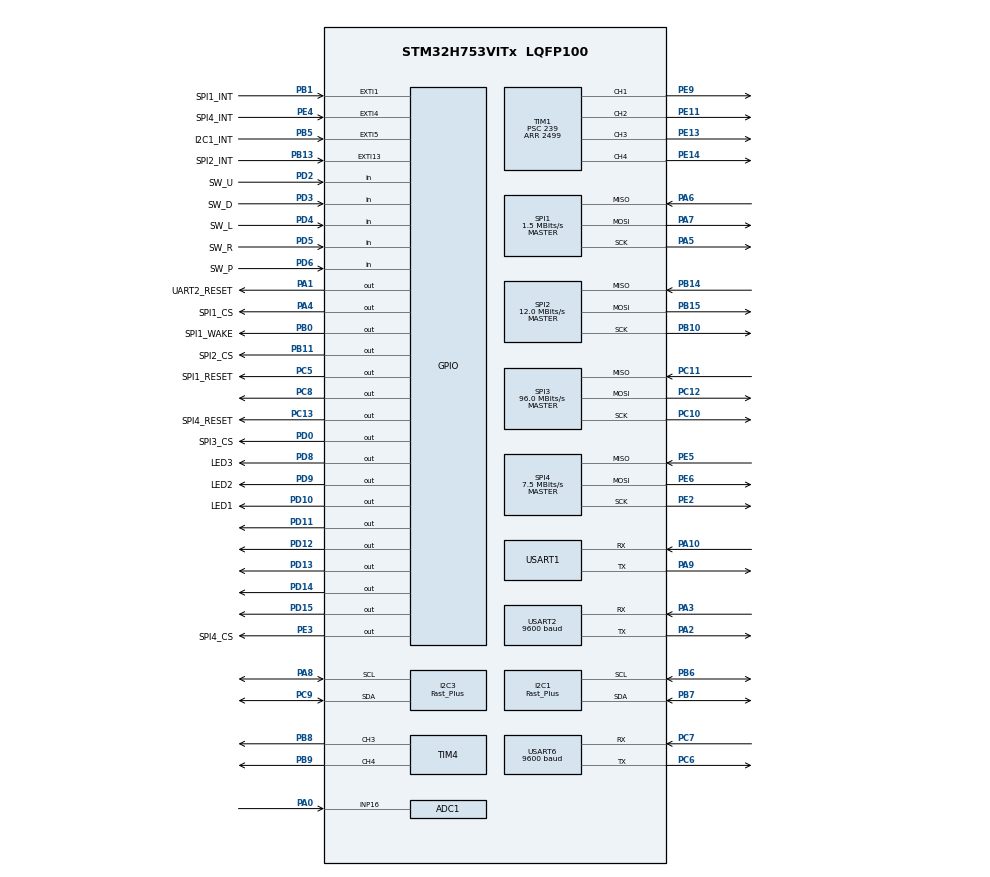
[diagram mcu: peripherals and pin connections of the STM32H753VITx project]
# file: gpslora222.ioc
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ADC1.Channel-0\#ChannelRegularConversion=ADC_CHANNEL_16
ADC1.NbrOfConversionFlag=1
ADC1.OffsetNumber-0\#ChannelRegularConversion=ADC_OFFSET_NONE
ADC1.OffsetSignedSaturation-0\#ChannelRegularConversion=DISABLE
ADC1.Rank-0\#ChannelRegularConversion=1
ADC1.SamplingTime-0\#ChannelRegularConversion=ADC_SAMPLETIME_1CYCLE_5
ADC1.master=1
CORTEX_M7.CPU_DCache=Disabled
CORTEX_M7.default_mode_Activation=1
Dma.I2C1_RX.6.Direction=DMA_PERIPH_TO_MEMORY
Dma.I2C1_RX.6.EventEnable=DISABLE
Dma.I2C1_RX.6.FIFOMode=DMA_FIFOMODE_DISABLE
Dma.I2C1_RX.6.Instance=DMA1_Stream6
Dma.I2C1_RX.6.MemDataAlignment=DMA_MDATAALIGN_BYTE
Dma.I2C1_RX.6.MemInc=DMA_MINC_ENABLE
Dma.I2C1_RX.6.Mode=DMA_NORMAL
Dma.I2C1_RX.6.PeriphDataAlignment=DMA_PDATAALIGN_BYTE
Dma.I2C1_RX.6.PeriphInc=DMA_PINC_DISABLE
Dma.I2C1_RX.6.Polarity=HAL_DMAMUX_REQ_GEN_RISING
Dma.I2C1_RX.6.Priority=DMA_PRIORITY_LOW
Dma.I2C1_RX.6.RequestNumber=1
Dma.I2C1_RX.6.SignalID=NONE
Dma.I2C1_RX.6.SyncEnable=DISABLE
Dma.I2C1_RX.6.SyncPolarity=HAL_DMAMUX_SYNC_NO_EVENT
Dma.I2C1_RX.6.SyncRequestNumber=1
Dma.I2C1_RX.6.SyncSignalID=NONE
Dma.I2C1_TX.5.Direction=DMA_MEMORY_TO_PERIPH
Dma.I2C1_TX.5.EventEnable=DISABLE
Dma.I2C1_TX.5.FIFOMode=DMA_FIFOMODE_DISABLE
Dma.I2C1_TX.5.Instance=DMA1_Stream5
Dma.I2C1_TX.5.MemDataAlignment=DMA_MDATAALIGN_BYTE
Dma.I2C1_TX.5.MemInc=DMA_MINC_ENABLE
Dma.I2C1_TX.5.Mode=DMA_NORMAL
Dma.I2C1_TX.5.PeriphDataAlignment=DMA_PDATAALIGN_BYTE
Dma.I2C1_TX.5.PeriphInc=DMA_PINC_DISABLE
Dma.I2C1_TX.5.Polarity=HAL_DMAMUX_REQ_GEN_RISING
Dma.I2C1_TX.5.Priority=DMA_PRIORITY_LOW
Dma.I2C1_TX.5.RequestNumber=1
Dma.I2C1_TX.5.SignalID=NONE
Dma.I2C1_TX.5.SyncEnable=DISABLE
Dma.I2C1_TX.5.SyncPolarity=HAL_DMAMUX_SYNC_NO_EVENT
Dma.I2C1_TX.5.SyncRequestNumber=1
Dma.I2C1_TX.5.SyncSignalID=NONE
Dma.I2C3_TX.2.Direction=DMA_MEMORY_TO_PERIPH
Dma.I2C3_TX.2.EventEnable=DISABLE
Dma.I2C3_TX.2.FIFOMode=DMA_FIFOMODE_DISABLE
Dma.I2C3_TX.2.Instance=DMA1_Stream2
Dma.I2C3_TX.2.MemDataAlignment=DMA_MDATAALIGN_BYTE
Dma.I2C3_TX.2.MemInc=DMA_MINC_ENABLE
Dma.I2C3_TX.2.Mode=DMA_NORMAL
Dma.I2C3_TX.2.PeriphDataAlignment=DMA_PDATAALIGN_BYTE
Dma.I2C3_TX.2.PeriphInc=DMA_PINC_DISABLE
Dma.I2C3_TX.2.Polarity=HAL_DMAMUX_REQ_GEN_RISING
Dma.I2C3_TX.2.Priority=DMA_PRIORITY_LOW
Dma.I2C3_TX.2.RequestNumber=1
Dma.I2C3_TX.2.SignalID=NONE
Dma.I2C3_TX.2.SyncEnable=DISABLE
Dma.I2C3_TX.2.SyncPolarity=HAL_DMAMUX_SYNC_NO_EVENT
Dma.I2C3_TX.2.SyncRequestNumber=1
Dma.I2C3_TX.2.SyncSignalID=NONE
Dma.Request0=SPI2_RX
Dma.Request1=SPI2_TX
Dma.Request2=I2C3_TX
Dma.Request3=USART1_TX
Dma.Request4=USART1_RX
Dma.Request5=I2C1_TX
Dma.Request6=I2C1_RX
Dma.Request7=USART6_RX
Dma.Request8=USART6_TX
Dma.SPI2_RX.0.Direction=DMA_PERIPH_TO_MEMORY
Dma.SPI2_RX.0.EventEnable=DISABLE
Dma.SPI2_RX.0.FIFOMode=DMA_FIFOMODE_DISABLE
Dma.SPI2_RX.0.Instance=DMA1_Stream0
Dma.SPI2_RX.0.MemDataAlignment=DMA_MDATAALIGN_BYTE
Dma.SPI2_RX.0.MemInc=DMA_MINC_ENABLE
Dma.SPI2_RX.0.Mode=DMA_NORMAL
Dma.SPI2_RX.0.PeriphDataAlignment=DMA_PDATAALIGN_BYTE
Dma.SPI2_RX.0.PeriphInc=DMA_PINC_DISABLE
Dma.SPI2_RX.0.Polarity=HAL_DMAMUX_REQ_GEN_RISING
Dma.SPI2_RX.0.Priority=DMA_PRIORITY_VERY_HIGH
Dma.SPI2_RX.0.RequestNumber=1
Dma.SPI2_RX.0.SignalID=NONE
Dma.SPI2_RX.0.SyncEnable=DISABLE
Dma.SPI2_RX.0.SyncPolarity=HAL_DMAMUX_SYNC_NO_EVENT
Dma.SPI2_RX.0.SyncRequestNumber=1
Dma.SPI2_RX.0.SyncSignalID=NONE
Dma.SPI2_TX.1.Direction=DMA_MEMORY_TO_PERIPH
Dma.SPI2_TX.1.EventEnable=DISABLE
Dma.SPI2_TX.1.FIFOMode=DMA_FIFOMODE_DISABLE
Dma.SPI2_TX.1.Instance=DMA1_Stream1
Dma.SPI2_TX.1.MemDataAlignment=DMA_MDATAALIGN_BYTE
Dma.SPI2_TX.1.MemInc=DMA_MINC_ENABLE
Dma.SPI2_TX.1.Mode=DMA_NORMAL
Dma.SPI2_TX.1.PeriphDataAlignment=DMA_PDATAALIGN_BYTE
Dma.SPI2_TX.1.PeriphInc=DMA_PINC_DISABLE
Dma.SPI2_TX.1.Polarity=HAL_DMAMUX_REQ_GEN_RISING
Dma.SPI2_TX.1.Priority=DMA_PRIORITY_HIGH
Dma.SPI2_TX.1.RequestNumber=1
Dma.SPI2_TX.1.SignalID=NONE
Dma.SPI2_TX.1.SyncEnable=DISABLE
Dma.SPI2_TX.1.SyncPolarity=HAL_DMAMUX_SYNC_NO_EVENT
Dma.SPI2_TX.1.SyncRequestNumber=1
Dma.SPI2_TX.1.SyncSignalID=NONE
Dma.USART1_RX.4.Direction=DMA_PERIPH_TO_MEMORY
Dma.USART1_RX.4.EventEnable=DISABLE
Dma.USART1_RX.4.FIFOMode=DMA_FIFOMODE_DISABLE
Dma.USART1_RX.4.Instance=DMA1_Stream4
Dma.USART1_RX.4.MemDataAlignment=DMA_MDATAALIGN_BYTE
Dma.USART1_RX.4.MemInc=DMA_MINC_ENABLE
Dma.USART1_RX.4.Mode=DMA_NORMAL
Dma.USART1_RX.4.PeriphDataAlignment=DMA_PDATAALIGN_BYTE
Dma.USART1_RX.4.PeriphInc=DMA_PINC_DISABLE
Dma.USART1_RX.4.Polarity=HAL_DMAMUX_REQ_GEN_RISING
Dma.USART1_RX.4.Priority=DMA_PRIORITY_LOW
Dma.USART1_RX.4.RequestNumber=1
Dma.USART1_RX.4.SignalID=NONE
Dma.USART1_RX.4.SyncEnable=DISABLE
Dma.USART1_RX.4.SyncPolarity=HAL_DMAMUX_SYNC_NO_EVENT
Dma.USART1_RX.4.SyncRequestNumber=1
Dma.USART1_RX.4.SyncSignalID=NONE
Dma.USART1_TX.3.Direction=DMA_MEMORY_TO_PERIPH
Dma.USART1_TX.3.EventEnable=DISABLE
Dma.USART1_TX.3.FIFOMode=DMA_FIFOMODE_DISABLE
Dma.USART1_TX.3.Instance=DMA1_Stream3
Dma.USART1_TX.3.MemDataAlignment=DMA_MDATAALIGN_BYTE
Dma.USART1_TX.3.MemInc=DMA_MINC_ENABLE
Dma.USART1_TX.3.Mode=DMA_NORMAL
Dma.USART1_TX.3.PeriphDataAlignment=DMA_PDATAALIGN_BYTE
Dma.USART1_TX.3.PeriphInc=DMA_PINC_DISABLE
Dma.USART1_TX.3.Polarity=HAL_DMAMUX_REQ_GEN_RISING
Dma.USART1_TX.3.Priority=DMA_PRIORITY_LOW
Dma.USART1_TX.3.RequestNumber=1
Dma.USART1_TX.3.SignalID=NONE
Dma.USART1_TX.3.SyncEnable=DISABLE
Dma.USART1_TX.3.SyncPolarity=HAL_DMAMUX_SYNC_NO_EVENT
Dma.USART1_TX.3.SyncRequestNumber=1
Dma.USART1_TX.3.SyncSignalID=NONE
Dma.USART6_RX.7.Direction=DMA_PERIPH_TO_MEMORY
Dma.USART6_RX.7.EventEnable=DISABLE
Dma.USART6_RX.7.FIFOMode=DMA_FIFOMODE_DISABLE
Dma.USART6_RX.7.Instance=DMA1_Stream7
Dma.USART6_RX.7.MemDataAlignment=DMA_MDATAALIGN_BYTE
Dma.USART6_RX.7.MemInc=DMA_MINC_ENABLE
Dma.USART6_RX.7.Mode=DMA_NORMAL
Dma.USART6_RX.7.PeriphDataAlignment=DMA_PDATAALIGN_BYTE
Dma.USART6_RX.7.PeriphInc=DMA_PINC_DISABLE
Dma.USART6_RX.7.Polarity=HAL_DMAMUX_REQ_GEN_RISING
Dma.USART6_RX.7.Priority=DMA_PRIORITY_LOW
Dma.USART6_RX.7.RequestNumber=1
Dma.USART6_RX.7.SignalID=NONE
Dma.USART6_RX.7.SyncEnable=DISABLE
Dma.USART6_RX.7.SyncPolarity=HAL_DMAMUX_SYNC_NO_EVENT
Dma.USART6_RX.7.SyncRequestNumber=1
Dma.USART6_RX.7.SyncSignalID=NONE
Dma.USART6_TX.8.Direction=DMA_MEMORY_TO_PERIPH
Dma.USART6_TX.8.EventEnable=DISABLE
Dma.USART6_TX.8.FIFOMode=DMA_FIFOMODE_DISABLE
Dma.USART6_TX.8.Instance=DMA2_Stream0
Dma.USART6_TX.8.MemDataAlignment=DMA_MDATAALIGN_BYTE
Dma.USART6_TX.8.MemInc=DMA_MINC_ENABLE
Dma.USART6_TX.8.Mode=DMA_NORMAL
Dma.USART6_TX.8.PeriphDataAlignment=DMA_PDATAALIGN_BYTE
Dma.USART6_TX.8.PeriphInc=DMA_PINC_DISABLE
Dma.USART6_TX.8.Polarity=HAL_DMAMUX_REQ_GEN_RISING
Dma.USART6_TX.8.Priority=DMA_PRIORITY_LOW
Dma.USART6_TX.8.RequestNumber=1
Dma.USART6_TX.8.SignalID=NONE
Dma.USART6_TX.8.SyncEnable=DISABLE
Dma.USART6_TX.8.SyncPolarity=HAL_DMAMUX_SYNC_NO_EVENT
Dma.USART6_TX.8.SyncRequestNumber=1
Dma.USART6_TX.8.SyncSignalID=NONE
I2C1.I2C_Speed_Mode=I2C_Fast_Plus
I2C1.Timing=0x0050174F
I2C3.I2C_Speed_Mode=I2C_Fast_Plus
I2C3.Timing=0x0050174F
Mcu.Family=STM32H7
Mcu.Name=STM32H753VITx
Mcu.Package=LQFP100
NVIC.DMA1_Stream0_IRQn=true\:0\:0\:false\:false\:true\:false\:true\:true
NVIC.DMA1_Stream1_IRQn=true\:0\:0\:false\:false\:true\:false\:true\:true
NVIC.DMA1_Stream2_IRQn=true\:0\:0\:false\:false\:true\:false\:true\:true
NVIC.DMA1_Stream3_IRQn=true\:0\:0\:false\:false\:true\:false\:true\:true
NVIC.DMA1_Stream4_IRQn=true\:0\:0\:false\:false\:true\:false\:true\:true
NVIC.DMA1_Stream5_IRQn=true\:0\:0\:false\:false\:true\:false\:true\:true
NVIC.DMA1_Stream6_IRQn=true\:0\:0\:false\:false\:true\:false\:true\:true
NVIC.DMA1_Stream7_IRQn=true\:0\:0\:false\:false\:true\:false\:true\:true
NVIC.DMA2_Stream0_IRQn=true\:0\:0\:false\:false\:true\:false\:true\:true
NVIC.EXTI15_10_IRQn=true\:0\:0\:false\:false\:true\:true\:true\:true
NVIC.EXTI1_IRQn=true\:0\:0\:false\:false\:true\:true\:true\:true
NVIC.EXTI4_IRQn=true\:0\:0\:false\:false\:true\:true\:true\:true
NVIC.EXTI9_5_IRQn=true\:0\:0\:false\:false\:true\:true\:true\:true
NVIC.I2C1_ER_IRQn=true\:0\:0\:false\:false\:true\:true\:true\:true
NVIC.I2C1_EV_IRQn=true\:0\:0\:false\:false\:true\:true\:true\:true
NVIC.I2C3_ER_IRQn=true\:0\:0\:false\:false\:true\:true\:true\:true
NVIC.I2C3_EV_IRQn=true\:0\:0\:false\:false\:true\:true\:true\:true
NVIC.PriorityGroup=NVIC_PRIORITYGROUP_4
NVIC.SPI2_IRQn=true\:0\:0\:false\:false\:true\:false\:true\:true
NVIC.TIM2_IRQn=true\:0\:0\:false\:false\:true\:true\:true\:true
NVIC.TIM3_IRQn=true\:0\:0\:false\:false\:true\:true\:true\:true
NVIC.USART1_IRQn=true\:0\:0\:false\:false\:true\:true\:true\:true
NVIC.USART2_IRQn=true\:0\:0\:false\:false\:true\:true\:true\:true
NVIC.USART6_IRQn=true\:0\:0\:false\:false\:true\:true\:true\:true
PA0.Mode=IN16-Single-Ended
PA0.Signal=ADC1_INP16
PA1.GPIO_Label=UART2_RESET
PA1.PinState=GPIO_PIN_SET
PA1.Signal=GPIO_Output
PA10.Mode=Asynchronous
PA10.Signal=USART1_RX
PA13\ (JTMS/SWDIO).Mode=Trace_Asynchronous_SW
PA13\ (JTMS/SWDIO).Signal=DEBUG_JTMS-SWDIO
PA14\ (JTCK/SWCLK).Mode=Trace_Asynchronous_SW
PA14\ (JTCK/SWCLK).Signal=DEBUG_JTCK-SWCLK
PA2.Mode=Asynchronous
PA2.Signal=USART2_TX
PA3.Mode=Asynchronous
PA3.Signal=USART2_RX
PA4.GPIO_Label=SPI1_CS
PA4.Signal=GPIO_Output
PA5.Mode=Full_Duplex_Master
PA5.Signal=SPI1_SCK
PA6.Mode=Full_Duplex_Master
PA6.Signal=SPI1_MISO
PA7.Mode=Full_Duplex_Master
PA7.Signal=SPI1_MOSI
PA8.Mode=I2C
PA8.Signal=I2C3_SCL
PA9.GPIO_PuPd=GPIO_PULLDOWN
PA9.Mode=Asynchronous
PA9.Signal=USART1_TX
PB0.GPIO_Label=SPI1_WAKE
PB0.Signal=GPIO_Output
PB1.GPIO_Label=SPI1_INT
PB1.Signal=GPXTI1
PB10.Mode=Full_Duplex_Master
PB10.Signal=SPI2_SCK
PB11.GPIO_Label=SPI2_CS
PB11.PinState=GPIO_PIN_SET
PB11.Signal=GPIO_Output
PB13.GPIO_Label=SPI2_INT
PB13.Signal=GPXTI13
PB14.Mode=Full_Duplex_Master
PB14.Signal=SPI2_MISO
PB15.Mode=Full_Duplex_Master
PB15.Signal=SPI2_MOSI
PB3\ (JTDO/TRACESWO).Mode=Trace_Asynchronous_SW
PB3\ (JTDO/TRACESWO).Signal=DEBUG_JTDO-SWO
PB5.GPIO_Label=I2C1_INT
PB5.Signal=GPXTI5
PB6.Mode=I2C
PB6.Signal=I2C1_SCL
PB7.Mode=I2C
PB7.Signal=I2C1_SDA
PB8.Signal=S_TIM4_CH3
PB9.Signal=S_TIM4_CH4
PC10.Mode=Full_Duplex_Master
PC10.Signal=SPI3_SCK
PC11.Mode=Full_Duplex_Master
PC11.Signal=SPI3_MISO
PC12.Mode=Full_Duplex_Master
PC12.Signal=SPI3_MOSI
PC13.GPIO_Label=SPI4_RESET
PC13.Signal=GPIO_Output
PC5.GPIO_Label=SPI1_RESET
PC5.Signal=GPIO_Output
PC6.Mode=Asynchronous
PC6.Signal=USART6_TX
PC7.Mode=Asynchronous
PC7.Signal=USART6_RX
PC8.Signal=GPIO_Output
PC9.Mode=I2C
PC9.Signal=I2C3_SDA
PD0.GPIO_Label=SPI3_CS
PD0.Signal=GPIO_Output
PD10.GPIO_Label=LED1
PD10.Signal=GPIO_Output
PD11.Signal=GPIO_Output
PD12.Signal=GPIO_Output
PD13.Signal=GPIO_Output
PD14.Signal=GPIO_Output
PD15.Signal=GPIO_Output
PD2.GPIO_Label=SW_U
PD2.GPIO_PuPd=GPIO_PULLUP
PD2.Signal=GPIO_Input
PD3.GPIO_Label=SW_D
PD3.GPIO_PuPd=GPIO_PULLUP
PD3.Signal=GPIO_Input
PD4.GPIO_Label=SW_L
PD4.GPIO_PuPd=GPIO_PULLUP
PD4.Signal=GPIO_Input
PD5.GPIO_Label=SW_R
PD5.GPIO_PuPd=GPIO_PULLUP
PD5.Signal=GPIO_Input
PD6.GPIO_Label=SW_P
PD6.GPIO_PuPd=GPIO_PULLUP
PD6.Signal=GPIO_Input
PD8.GPIO_Label=LED3
PD8.Signal=GPIO_Output
PD9.GPIO_Label=LED2
PD9.Signal=GPIO_Output
PE11.Signal=S_TIM1_CH2
PE13.Signal=S_TIM1_CH3
PE14.Signal=S_TIM1_CH4
PE2.Mode=Full_Duplex_Master
PE2.Signal=SPI4_SCK
PE3.GPIO_Label=SPI4_CS
PE3.Signal=GPIO_Output
PE4.GPIO_Label=SPI4_INT
PE4.Signal=GPXTI4
PE5.Mode=Full_Duplex_Master
PE5.Signal=SPI4_MISO
PE6.Mode=Full_Duplex_Master
PE6.Signal=SPI4_MOSI
PE9.Signal=S_TIM1_CH1
PH0-OSC_IN\ (PH0).Mode=HSE-External-Clock-Source
PH0-OSC_IN\ (PH0).Signal=RCC_OSC_IN
ProjectManager.HeapSize=0x200
ProjectManager.StackSize=0x400
ProjectManager.TargetToolchain=STM32CubeIDE
RCC.ADCFreq_Value=75000000
RCC.APB1Freq_Value=120000000
RCC.APB2Freq_Value=120000000
RCC.APB3Freq_Value=120000000
RCC.APB4Freq_Value=120000000
RCC.CortexFreq_Value=480000000
RCC.D1PPRE=RCC_APB3_DIV2
RCC.D2PPRE1=RCC_APB1_DIV2
RCC.D2PPRE2=RCC_APB2_DIV2
RCC.D3PPRE=RCC_APB4_DIV2
RCC.DIVM1=5
RCC.DIVM2=2
RCC.DIVN1=192
RCC.DIVN2=12
RCC.DIVQ1=5
RCC.HCLKFreq_Value=240000000
RCC.HPRE=RCC_HCLK_DIV2
RCC.PLL2FRACN=0
RCC.PLL3FRACN=0
RCC.PLLFRACN=0
RCC.PLLSourceVirtual=RCC_PLLSOURCE_HSE
RCC.SYSCLKFreq_VALUE=480000000
RCC.SYSCLKSource=RCC_SYSCLKSOURCE_PLLCLK
RCC.USBFreq_Value=192000000
SH.S_TIM1_CH1.0=TIM1_CH1,PWM Generation1 CH1
SH.S_TIM1_CH2.0=TIM1_CH2,PWM Generation2 CH2
SH.S_TIM1_CH3.0=TIM1_CH3,PWM Generation3 CH3
SH.S_TIM1_CH4.0=TIM1_CH4,PWM Generation4 CH4
SH.S_TIM4_CH3.0=TIM4_CH3,PWM Generation3 CH3
SH.S_TIM4_CH4.0=TIM4_CH4,PWM Generation4 CH4
SPI1.BaudRatePrescaler=SPI_BAUDRATEPRESCALER_128
SPI1.CLKPhase=SPI_PHASE_2EDGE
SPI1.CLKPolarity=SPI_POLARITY_HIGH
SPI1.CalculateBaudRate=1.5 MBits/s
SPI1.DataSize=SPI_DATASIZE_8BIT
SPI1.Direction=SPI_DIRECTION_2LINES
SPI1.Mode=SPI_MODE_MASTER
SPI1.VirtualType=VM_MASTER
SPI2.BaudRatePrescaler=SPI_BAUDRATEPRESCALER_16
SPI2.CLKPhase=SPI_PHASE_2EDGE
SPI2.CLKPolarity=SPI_POLARITY_HIGH
SPI2.CalculateBaudRate=12.0 MBits/s
SPI2.DataSize=SPI_DATASIZE_8BIT
SPI2.Direction=SPI_DIRECTION_2LINES
SPI2.Mode=SPI_MODE_MASTER
SPI2.NSSPMode=SPI_NSS_PULSE_ENABLE
SPI2.VirtualType=VM_MASTER
SPI3.CalculateBaudRate=96.0 MBits/s
SPI3.Direction=SPI_DIRECTION_2LINES
SPI3.Mode=SPI_MODE_MASTER
SPI3.VirtualType=VM_MASTER
SPI4.BaudRatePrescaler=SPI_BAUDRATEPRESCALER_16
SPI4.CalculateBaudRate=7.5 MBits/s
SPI4.DataSize=SPI_DATASIZE_8BIT
SPI4.Direction=SPI_DIRECTION_2LINES
SPI4.Mode=SPI_MODE_MASTER
SPI4.VirtualType=VM_MASTER
TIM1.Channel-PWM\ Generation1\ CH1=TIM_CHANNEL_1
TIM1.Channel-PWM\ Generation2\ CH2=TIM_CHANNEL_2
TIM1.Channel-PWM\ Generation3\ CH3=TIM_CHANNEL_3
TIM1.Channel-PWM\ Generation4\ CH4=TIM_CHANNEL_4
TIM1.Period=2499
TIM1.Prescaler=239
TIM1.Pulse-PWM\ Generation2\ CH2=0
TIM1.Pulse-PWM\ Generation3\ CH3=0
TIM1.Pulse-PWM\ Generation4\ CH4=0
TIM2.Period=499
TIM2.Prescaler=239
TIM3.Period=99
TIM3.Prescaler=23999
TIM4.Channel-PWM\ Generation3\ CH3=TIM_CHANNEL_3
TIM4.Channel-PWM\ Generation4\ CH4=TIM_CHANNEL_4
USART1.SwapParam=ADVFEATURE_SWAP_ENABLE
USART1.VirtualMode-Asynchronous=VM_ASYNC
USART2.BaudRate=9600
USART2.VirtualMode-Asynchronous=VM_ASYNC
USART6.BaudRate=9600
USART6.VirtualMode=VM_ASYNC
VP_MEMORYMAP_VS_MEMORYMAP.Mode=CurAppReg
VP_TIM2_VS_ClockSourceINT.Mode=Internal
VP_TIM3_VS_ClockSourceINT.Mode=Internal
board=custom

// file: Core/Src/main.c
/* USER CODE BEGIN Header */
/**
 ******************************************************************************
 * @file           : main.c
 * @brief          : Main program body
 ******************************************************************************
 * @attention
 *
 * Copyright (c) 2026 STMicroelectronics.
 * All rights reserved.
 *
 * This software is licensed under terms that can be found in the LICENSE file
 * in the root directory of this software component.
 * If no LICENSE file comes with this software, it is provided AS-IS.
 *
 ******************************************************************************
 */
/* USER CODE END Header */
#include "main.h"

/* USER CODE BEGIN Includes */
#include "bno085.h"
#include "debug.h"
#include "gnss.h"
#include "motor.h"
#include "oled.h"
#include "sensor.h"
#include "uav_link.h"
#include "stm32h7xx_hal_gpio.h"
#include "switch.h"
#include "uart_bridge.h"

/* USER CODE END Includes */

ADC_HandleTypeDef hadc1;

I2C_HandleTypeDef hi2c1;
I2C_HandleTypeDef hi2c3;
DMA_HandleTypeDef hdma_i2c1_tx;
DMA_HandleTypeDef hdma_i2c1_rx;
DMA_HandleTypeDef hdma_i2c3_tx;

SPI_HandleTypeDef hspi1;
SPI_HandleTypeDef hspi2;
SPI_HandleTypeDef hspi3;
SPI_HandleTypeDef hspi4;
DMA_HandleTypeDef hdma_spi2_rx;
DMA_HandleTypeDef hdma_spi2_tx;

TIM_HandleTypeDef htim1;
TIM_HandleTypeDef htim2;
TIM_HandleTypeDef htim3;
TIM_HandleTypeDef htim4;

UART_HandleTypeDef huart1;
UART_HandleTypeDef huart2;
UART_HandleTypeDef huart6;
DMA_HandleTypeDef hdma_usart1_tx;
DMA_HandleTypeDef hdma_usart1_rx;
DMA_HandleTypeDef hdma_usart6_rx;
DMA_HandleTypeDef hdma_usart6_tx;

/* USER CODE BEGIN PV */

#define BATTERY_FILTER_SIZE 20

uint16_t adc_buffer[BATTERY_FILTER_SIZE];
uint8_t adc_index = 0;
uint8_t filter_filled = 0;

float battery_voltage = 0.0f;
int8_t battery_percent = 0;
uint32_t last_battery_check_time = 0;

uint32_t user_step_throttle_compare = 1000U;
static gnss_pvt_t gnss_pvt;
static uint8_t user_gnss_bridge_mode = 0U;
static uint8_t user_gps_lora_test_mode = 0U;

/* USER CODE END PV */

void SystemClock_Config(void);
static void MPU_Config(void);
static void MX_GPIO_Init(void);
static void MX_DMA_Init(void);
static void MX_SPI1_Init(void);
static void MX_SPI2_Init(void);
static void MX_SPI3_Init(void);
static void MX_SPI4_Init(void);
static void MX_USART1_UART_Init(void);
static void MX_USART2_UART_Init(void);
static void MX_I2C1_Init(void);
static void MX_I2C3_Init(void);
static void MX_TIM1_Init(void);
static void MX_ADC1_Init(void);
static void MX_TIM4_Init(void);
static void MX_TIM3_Init(void);
static void MX_TIM2_Init(void);
static void MX_USART6_UART_Init(void);

/* USER CODE BEGIN 0 */

static uint32_t gps_coordinate_magnitude(int32_t coordinate)
{
  return (coordinate < 0) ? (uint32_t)(-(int64_t)coordinate) : (uint32_t)coordinate;
}

static void gps_lora_test_log_pvt(const gnss_pvt_t *pvt)
{
  static uint32_t last_log_ms;
  static uint8_t last_valid = 0xFFU;
  uint8_t valid;
  uint32_t now;
  uint32_t lat;
  uint32_t lon;

  if (pvt == NULL)
  {
    return;
  }

  valid = ((pvt->fix_ok != 0U) && (pvt->fix_type >= 2U)) ? 1U : 0U;
  now = HAL_GetTick();
  if ((valid == last_valid) && ((now - last_log_ms) < 2000U))
  {
    return;
  }

  last_valid = valid;
  last_log_ms = now;
  if (valid == 0U)
  {
    (void)uart1_printf("[GPS] NO FIX type=%u satellites=%u\r\n",
                       pvt->fix_type, pvt->satellites_used);
    return;
  }

  lat = gps_coordinate_magnitude(pvt->latitude_deg_1e7);
  lon = gps_coordinate_magnitude(pvt->longitude_deg_1e7);
  (void)uart1_printf("[GPS] FIX VALID type=%u satellites=%u\r\n",
                     pvt->fix_type, pvt->satellites_used);
  (void)uart1_printf("[GPS] LAT=%s%lu.%07lu LON=%s%lu.%07lu\r\n",
                     (pvt->latitude_deg_1e7 < 0) ? "-" : "",
                     (unsigned long)(lat / 10000000U),
                     (unsigned long)(lat % 10000000U),
                     (pvt->longitude_deg_1e7 < 0) ? "-" : "",
                     (unsigned long)(lon / 10000000U),
                     (unsigned long)(lon % 10000000U));
}

void Battery_Process(void) {
  if (HAL_GetTick() - last_battery_check_time >= 50) {
    last_battery_check_time = HAL_GetTick();

    HAL_ADC_Start(&hadc1);
    if (HAL_ADC_PollForConversion(&hadc1, 10) == HAL_OK) {
      uint32_t raw_adc = HAL_ADC_GetValue(&hadc1);

      adc_buffer[adc_index] = raw_adc;
      adc_index++;
      if (adc_index >= BATTERY_FILTER_SIZE) {
        adc_index = 0;
        filter_filled = 1;
      }

      if (filter_filled || adc_index > 5) {
        uint32_t sum = 0;
        uint8_t count = filter_filled ? BATTERY_FILTER_SIZE : adc_index;

        for (int i = 0; i < count; i++) {
          sum += adc_buffer[i];
        }

        float avg_adc = (float)sum / count;

        // 실제 전압(16.0V, 13.8V) 대비 측정값이 항상 0.2V 높게 나오는 현상(16.2V, 14.0V) 오프셋 보정
        float raw_voltage = (avg_adc / 65535.0f) * 3.3f * 5.7f;
        battery_voltage = raw_voltage - 0.2f;

        float percent = (battery_voltage - 13.2f) / (16.8f - 13.2f) * 100.0f;
        if (percent > 100.0f) percent = 100.0f;
        if (percent < 0.0f) percent = 0.0f;

        battery_percent = (int8_t)percent;
      }
    }
    HAL_ADC_Stop(&hadc1);
  }
}

void HAL_TIM_PeriodElapsedCallback(TIM_HandleTypeDef *htim) {
  if (htim == NULL) {
    return;
  }
  if (htim->Instance == TIM2) {
    if (main_flag < UINT32_MAX) {
      main_flag++;
    }
  }
  if (htim->Instance == TIM3) {
    debug_oled_tick_divider++;

    if (debug_oled_tick_divider >= 5U) {
      debug_oled_tick_divider = 0U;
      debug_oled_update_flag = 1U;
      debug_uart6_update_flag = 1U;
    }
  }
}
/* USER CODE END 0 */

int main(void)
{

  /* MPU Configuration--------------------------------------------------------*/
  MPU_Config();

  /* MCU Configuration--------------------------------------------------------*/

  /* Reset of all peripherals, Initializes the Flash interface and the Systick. */
  HAL_Init();

  /* Configure the system clock */
  SystemClock_Config();

  /* Initialize all configured peripherals */
  MX_GPIO_Init();
  MX_DMA_Init();
  MX_SPI1_Init();
  MX_SPI2_Init();
  MX_SPI3_Init();
  MX_SPI4_Init();
  MX_USART1_UART_Init();
  MX_USART2_UART_Init();
  MX_I2C1_Init();
  MX_I2C3_Init();
  MX_TIM1_Init();
  MX_ADC1_Init();
  MX_TIM4_Init();
  MX_TIM3_Init();
  MX_TIM2_Init();
  MX_USART6_UART_Init();
  /* USER CODE BEGIN 2 */

  uart1_printf("\r\n\r\n");
	uart1_printf(" ======== ★☆ Drone Firmware ★☆ ========\r\n");
	uart1_printf("=====  BackStudyMaster Lim Song ju  ======\r\n");
	uart1_printf("================ STM32H753 ===============\r\n");

  switch_init();
  OLED_Init();
  OLED_Clear();
  OLED_Printf(2, 0, "System Start!");
  OLED_Printf(4, 0, "UP:FLY RT:BRIDGE");
  OLED_Printf(6, 0, "LT:GPS+LoRa TEST");
  OLED_Update();
  while (1) {
    switch_update();
    if (sw_u_flag == 1) {
      OLED_Clear();
      OLED_Printf(4, 0, "Loading...");
      OLED_Update();
      break;
    }

    if (sw_r_flag == 1U) {
      user_gnss_bridge_mode = 1U;
      OLED_Clear();
      OLED_Printf(3, 0, "GNSS Bridge");
      OLED_Printf(5, 0, "Starting...");
      OLED_Update();
      break;
    }

    if (sw_l_flag == 1U) {
      user_gps_lora_test_mode = 1U;
      OLED_Clear();
      OLED_Printf(2, 0, "GPS + LoRa TEST");
      OLED_Printf(5, 0, "Starting...");
      OLED_Update();
      break;
    }
  }
  HAL_Delay(2000);

  if (user_gps_lora_test_mode != 0U) {
    uint8_t lora_ready = 0U;

    switch_init();
    debug_init();
    (void)uart1_printf("\r\n[UAV] GPS + LoRa TEST START\r\n");
    if (gnss_init() == HAL_OK) {
      (void)uart1_printf("[GPS] UART initialized: USART2 115200, interrupt RX\r\n");
    } else {
      (void)uart1_printf("[GPS] UART INIT ERROR\r\n");
    }

    if (uav_link_init() == HAL_OK) {
      lora_ready = 1U;
      OLED_Clear();
      OLED_Printf(2, 0, "GPS + LoRa TEST");
      OLED_Printf(4, 0, "LoRa RX READY");
      OLED_Update();
    } else {
      OLED_Clear();
      OLED_Printf(2, 0, "GPS + LoRa TEST");
      OLED_Printf(4, 0, "LoRa INIT ERROR");
      OLED_Update();
    }

    while (1) {
      if (gnss_read_pvt(&gnss_pvt)) {
        uav_link_update_gnss(&gnss_pvt);
        gps_lora_test_log_pvt(&gnss_pvt);
      }
      if (lora_ready != 0U) {
        uav_link_process();
      }
    }
  }

  if (user_gnss_bridge_mode != 0U) {
    switch_init();
    debug_init();
    uart_bridge_init();

    if (gnss_init() != HAL_OK) {
      OLED_Clear();
      OLED_Printf(3, 0, "GNSS INIT ERR");
      OLED_Update();
      Error_Handler();
    }

    OLED_Clear();
    OLED_Printf(2, 0, "GNSS Bridge On");
    OLED_Printf(4, 0, "PC: UART1");
    OLED_Printf(5, 0, "GNSS: UART2");
    OLED_Update();

    uart_bridge_set_active(true);
    debug_set_bridge_mode(1U);
    gnss_set_bridge_mode(1U);

    while (1) {
      uart_bridge_process();
    }
  }

  while (sensor_init() != HAL_OK) {
    //(void)uart1_printf("sensor init retry\r\n");
    HAL_Delay(100U);
  }

  //(void)uart1_printf("sensor init ok\r\n");

  //(void)uart1_printf("oled init ok\r\n");

  switch_init();
  //(void)uart1_printf("switch init ok\r\n");
  debug_init();
  uart_bridge_init();
  (void)bno085_communication_test();
  if (gnss_init() == HAL_OK) {
    (void)uart1_printf("gnss init ok\r\n");
  } else {
    (void)uart1_printf("gnss init error\r\n");
  }
  //(void)uart1_printf("debug init ok\r\n");

  //(void)uart1_printf("System Start\r\n");

  (void)HAL_TIM_Base_Start_IT(&htim2);
  (void)HAL_TIM_Base_Start_IT(&htim3);

  motor_init(&htim1);

  /* USER CODE END 2 */

  /* Infinite loop */
  while (1) {

    /* USER CODE BEGIN 3 */
    Battery_Process();
    sensor_process();
    (void)bno085_process();
    switch_update();
    debug_process();
    uart_bridge_process();
    if (gnss_read_pvt(&gnss_pvt)) {
      (void)uart1_printf("[GPS] FIX=%u OK=%u SV=%u hMSL=%ld hAcc=%lu vAcc=%lu gSpd=%ld\r\n",
                         gnss_pvt.fix_type,
                         gnss_pvt.fix_ok,
                         gnss_pvt.satellites_used,
                         gnss_pvt.height_msl_mm,
                         gnss_pvt.horizontal_accuracy_mm,
                         gnss_pvt.vertical_accuracy_mm,
                         gnss_pvt.ground_speed_mm_s);
      (void)uart1_printf("[GPS] LAT=%ld\r\n[GPS] LON=%ld\r\n",
                         gnss_pvt.latitude_deg_1e7,
                         gnss_pvt.longitude_deg_1e7);
    }
    // GPS 모듈을 UBX(바이너리) 프로토콜 전용으로 설정했으므로,
    // 바이너리 데이터 내부의 random '$' 문자로 인해 수신되는 가짜 NMEA 문자열 출력 차단
    // if (gnss_read_line(gnss_sentence, sizeof(gnss_sentence))) {
    //   (void)uart1_printf("%s\r\n", gnss_sentence);
    // }
    //if (imuimu == 1) {
    //  (void)uart1_printf("IMU\r\n");
    //}
    if (sw_u_flag) {
      HAL_Delay(100);
      motor_reset_rate_pid();
      motor_set_throttle(1060U);
      motor_set_rate_targets(0, 0, 0);
      while (1) {
        switch_update();
        debug_process();
        if (main_flag != 0U) {
          main_flag--;
          sensor_process();
          (void)bno085_process();
          motor_rate_pid_update();
        }

        if (sw_d_flag) {
          motor_stop();
          break;
        }
      }
    }
  }
  /* USER CODE END 3 */
}

void SystemClock_Config(void)
{
  RCC_OscInitTypeDef RCC_OscInitStruct = {0};
  RCC_ClkInitTypeDef RCC_ClkInitStruct = {0};

  /** Supply configuration update enable
  */
  HAL_PWREx_ConfigSupply(PWR_LDO_SUPPLY);

  /** Configure the main internal regulator output voltage
  */
  __HAL_PWR_VOLTAGESCALING_CONFIG(PWR_REGULATOR_VOLTAGE_SCALE0);

  while(!__HAL_PWR_GET_FLAG(PWR_FLAG_VOSRDY)) {}

  /** Initializes the RCC Oscillators according to the specified parameters
  * in the RCC_OscInitTypeDef structure.
  */
  RCC_OscInitStruct.OscillatorType = RCC_OSCILLATORTYPE_HSE;
  RCC_OscInitStruct.HSEState = RCC_HSE_BYPASS;
  RCC_OscInitStruct.PLL.PLLState = RCC_PLL_ON;
  RCC_OscInitStruct.PLL.PLLSource = RCC_PLLSOURCE_HSE;
  RCC_OscInitStruct.PLL.PLLM = 5;
  RCC_OscInitStruct.PLL.PLLN = 192;
  RCC_OscInitStruct.PLL.PLLP = 2;
  RCC_OscInitStruct.PLL.PLLQ = 5;
  RCC_OscInitStruct.PLL.PLLR = 2;
  RCC_OscInitStruct.PLL.PLLRGE = RCC_PLL1VCIRANGE_2;
  RCC_OscInitStruct.PLL.PLLVCOSEL = RCC_PLL1VCOWIDE;
  RCC_OscInitStruct.PLL.PLLFRACN = 0;
  if (HAL_RCC_OscConfig(&RCC_OscInitStruct) != HAL_OK)
  {
    Error_Handler();
  }

  /** Initializes the CPU, AHB and APB buses clocks
  */
  RCC_ClkInitStruct.ClockType = RCC_CLOCKTYPE_HCLK|RCC_CLOCKTYPE_SYSCLK
                              |RCC_CLOCKTYPE_PCLK1|RCC_CLOCKTYPE_PCLK2
                              |RCC_CLOCKTYPE_D3PCLK1|RCC_CLOCKTYPE_D1PCLK1;
  RCC_ClkInitStruct.SYSCLKSource = RCC_SYSCLKSOURCE_PLLCLK;
  RCC_ClkInitStruct.SYSCLKDivider = RCC_SYSCLK_DIV1;
  RCC_ClkInitStruct.AHBCLKDivider = RCC_HCLK_DIV2;
  RCC_ClkInitStruct.APB3CLKDivider = RCC_APB3_DIV2;
  RCC_ClkInitStruct.APB1CLKDivider = RCC_APB1_DIV2;
  RCC_ClkInitStruct.APB2CLKDivider = RCC_APB2_DIV2;
  RCC_ClkInitStruct.APB4CLKDivider = RCC_APB4_DIV2;

  if (HAL_RCC_ClockConfig(&RCC_ClkInitStruct, FLASH_LATENCY_4) != HAL_OK)
  {
    Error_Handler();
  }
}

static void MX_ADC1_Init(void)
{

  ADC_MultiModeTypeDef multimode = {0};
  ADC_ChannelConfTypeDef sConfig = {0};

  /** Common config
  */
  hadc1.Instance = ADC1;
  hadc1.Init.ClockPrescaler = ADC_CLOCK_ASYNC_DIV1;
  hadc1.Init.Resolution = ADC_RESOLUTION_16B;
  hadc1.Init.ScanConvMode = ADC_SCAN_DISABLE;
  hadc1.Init.EOCSelection = ADC_EOC_SINGLE_CONV;
  hadc1.Init.LowPowerAutoWait = DISABLE;
  hadc1.Init.ContinuousConvMode = DISABLE;
  hadc1.Init.NbrOfConversion = 1;
  hadc1.Init.DiscontinuousConvMode = DISABLE;
  hadc1.Init.ExternalTrigConv = ADC_SOFTWARE_START;
  hadc1.Init.ExternalTrigConvEdge = ADC_EXTERNALTRIGCONVEDGE_NONE;
  hadc1.Init.ConversionDataManagement = ADC_CONVERSIONDATA_DR;
  hadc1.Init.Overrun = ADC_OVR_DATA_PRESERVED;
  hadc1.Init.LeftBitShift = ADC_LEFTBITSHIFT_NONE;
  hadc1.Init.OversamplingMode = DISABLE;
  hadc1.Init.Oversampling.Ratio = 1;
  if (HAL_ADC_Init(&hadc1) != HAL_OK)
  {
    Error_Handler();
  }

  /** Configure the ADC multi-mode
  */
  multimode.Mode = ADC_MODE_INDEPENDENT;
  if (HAL_ADCEx_MultiModeConfigChannel(&hadc1, &multimode) != HAL_OK)
  {
    Error_Handler();
  }

  /** Configure Regular Channel
  */
  sConfig.Channel = ADC_CHANNEL_16;
  sConfig.Rank = ADC_REGULAR_RANK_1;
  sConfig.SamplingTime = ADC_SAMPLETIME_1CYCLE_5;
  sConfig.SingleDiff = ADC_SINGLE_ENDED;
  sConfig.OffsetNumber = ADC_OFFSET_NONE;
  sConfig.Offset = 0;
  sConfig.OffsetSignedSaturation = DISABLE;
  if (HAL_ADC_ConfigChannel(&hadc1, &sConfig) != HAL_OK)
  {
    Error_Handler();
  }

}

static void MX_I2C1_Init(void)
{

  hi2c1.Instance = I2C1;
  hi2c1.Init.Timing = 0x0050174F;
  hi2c1.Init.OwnAddress1 = 0;
  hi2c1.Init.AddressingMode = I2C_ADDRESSINGMODE_7BIT;
  hi2c1.Init.DualAddressMode = I2C_DUALADDRESS_DISABLE;
  hi2c1.Init.OwnAddress2 = 0;
  hi2c1.Init.OwnAddress2Masks = I2C_OA2_NOMASK;
  hi2c1.Init.GeneralCallMode = I2C_GENERALCALL_DISABLE;
  hi2c1.Init.NoStretchMode = I2C_NOSTRETCH_DISABLE;
  if (HAL_I2C_Init(&hi2c1) != HAL_OK)
  {
    Error_Handler();
  }

  /** Configure Analogue filter
  */
  if (HAL_I2CEx_ConfigAnalogFilter(&hi2c1, I2C_ANALOGFILTER_ENABLE) != HAL_OK)
  {
    Error_Handler();
  }

  /** Configure Digital filter
  */
  if (HAL_I2CEx_ConfigDigitalFilter(&hi2c1, 0) != HAL_OK)
  {
    Error_Handler();
  }

  /** I2C Enable Fast Mode Plus
  */
  HAL_I2CEx_EnableFastModePlus(I2C_FASTMODEPLUS_I2C1);

}

static void MX_I2C3_Init(void)
{

  hi2c3.Instance = I2C3;
  hi2c3.Init.Timing = 0x0050174F;
  hi2c3.Init.OwnAddress1 = 0;
  hi2c3.Init.AddressingMode = I2C_ADDRESSINGMODE_7BIT;
  hi2c3.Init.DualAddressMode = I2C_DUALADDRESS_DISABLE;
  hi2c3.Init.OwnAddress2 = 0;
  hi2c3.Init.OwnAddress2Masks = I2C_OA2_NOMASK;
  hi2c3.Init.GeneralCallMode = I2C_GENERALCALL_DISABLE;
  hi2c3.Init.NoStretchMode = I2C_NOSTRETCH_DISABLE;
  if (HAL_I2C_Init(&hi2c3) != HAL_OK)
  {
    Error_Handler();
  }

  /** Configure Analogue filter
  */
  if (HAL_I2CEx_ConfigAnalogFilter(&hi2c3, I2C_ANALOGFILTER_ENABLE) != HAL_OK)
  {
    Error_Handler();
  }

  /** Configure Digital filter
  */
  if (HAL_I2CEx_ConfigDigitalFilter(&hi2c3, 0) != HAL_OK)
  {
    Error_Handler();
  }

  /** I2C Enable Fast Mode Plus
  */
  HAL_I2CEx_EnableFastModePlus(I2C_FASTMODEPLUS_I2C3);

}

static void MX_SPI1_Init(void)
{

  /* SPI1 parameter configuration*/
  hspi1.Instance = SPI1;
  hspi1.Init.Mode = SPI_MODE_MASTER;
  hspi1.Init.Direction = SPI_DIRECTION_2LINES;
  hspi1.Init.DataSize = SPI_DATASIZE_8BIT;
  hspi1.Init.CLKPolarity = SPI_POLARITY_HIGH;
  hspi1.Init.CLKPhase = SPI_PHASE_2EDGE;
  hspi1.Init.NSS = SPI_NSS_SOFT;
  hspi1.Init.BaudRatePrescaler = SPI_BAUDRATEPRESCALER_128;
  hspi1.Init.FirstBit = SPI_FIRSTBIT_MSB;
  hspi1.Init.TIMode = SPI_TIMODE_DISABLE;
  hspi1.Init.CRCCalculation = SPI_CRCCALCULATION_DISABLE;
  hspi1.Init.CRCPolynomial = 0x0;
  hspi1.Init.NSSPMode = SPI_NSS_PULSE_ENABLE;
  hspi1.Init.NSSPolarity = SPI_NSS_POLARITY_LOW;
  hspi1.Init.FifoThreshold = SPI_FIFO_THRESHOLD_01DATA;
  hspi1.Init.TxCRCInitializationPattern = SPI_CRC_INITIALIZATION_ALL_ZERO_PATTERN;
  hspi1.Init.RxCRCInitializationPattern = SPI_CRC_INITIALIZATION_ALL_ZERO_PATTERN;
  hspi1.Init.MasterSSIdleness = SPI_MASTER_SS_IDLENESS_00CYCLE;
  hspi1.Init.MasterInterDataIdleness = SPI_MASTER_INTERDATA_IDLENESS_00CYCLE;
  hspi1.Init.MasterReceiverAutoSusp = SPI_MASTER_RX_AUTOSUSP_DISABLE;
  hspi1.Init.MasterKeepIOState = SPI_MASTER_KEEP_IO_STATE_DISABLE;
  hspi1.Init.IOSwap = SPI_IO_SWAP_DISABLE;
  if (HAL_SPI_Init(&hspi1) != HAL_OK)
  {
    Error_Handler();
  }

}

static void MX_SPI2_Init(void)
{

  /* SPI2 parameter configuration*/
  hspi2.Instance = SPI2;
  hspi2.Init.Mode = SPI_MODE_MASTER;
  hspi2.Init.Direction = SPI_DIRECTION_2LINES;
  hspi2.Init.DataSize = SPI_DATASIZE_8BIT;
  hspi2.Init.CLKPolarity = SPI_POLARITY_HIGH;
  hspi2.Init.CLKPhase = SPI_PHASE_2EDGE;
  hspi2.Init.NSS = SPI_NSS_SOFT;
  hspi2.Init.BaudRatePrescaler = SPI_BAUDRATEPRESCALER_16;
  hspi2.Init.FirstBit = SPI_FIRSTBIT_MSB;
  hspi2.Init.TIMode = SPI_TIMODE_DISABLE;
  hspi2.Init.CRCCalculation = SPI_CRCCALCULATION_DISABLE;
  hspi2.Init.CRCPolynomial = 0x0;
  hspi2.Init.NSSPMode = SPI_NSS_PULSE_ENABLE;
  hspi2.Init.NSSPolarity = SPI_NSS_POLARITY_LOW;
  hspi2.Init.FifoThreshold = SPI_FIFO_THRESHOLD_01DATA;
  hspi2.Init.TxCRCInitializationPattern = SPI_CRC_INITIALIZATION_ALL_ZERO_PATTERN;
  hspi2.Init.RxCRCInitializationPattern = SPI_CRC_INITIALIZATION_ALL_ZERO_PATTERN;
  hspi2.Init.MasterSSIdleness = SPI_MASTER_SS_IDLENESS_00CYCLE;
  hspi2.Init.MasterInterDataIdleness = SPI_MASTER_INTERDATA_IDLENESS_00CYCLE;
  hspi2.Init.MasterReceiverAutoSusp = SPI_MASTER_RX_AUTOSUSP_DISABLE;
  hspi2.Init.MasterKeepIOState = SPI_MASTER_KEEP_IO_STATE_DISABLE;
  hspi2.Init.IOSwap = SPI_IO_SWAP_DISABLE;
  if (HAL_SPI_Init(&hspi2) != HAL_OK)
  {
    Error_Handler();
  }

}

static void MX_SPI3_Init(void)
{

  /* SPI3 parameter configuration*/
  hspi3.Instance = SPI3;
  hspi3.Init.Mode = SPI_MODE_MASTER;
  hspi3.Init.Direction = SPI_DIRECTION_2LINES;
  hspi3.Init.DataSize = SPI_DATASIZE_4BIT;
  hspi3.Init.CLKPolarity = SPI_POLARITY_LOW;
  hspi3.Init.CLKPhase = SPI_PHASE_1EDGE;
  hspi3.Init.NSS = SPI_NSS_SOFT;
  hspi3.Init.BaudRatePrescaler = SPI_BAUDRATEPRESCALER_2;
  hspi3.Init.FirstBit = SPI_FIRSTBIT_MSB;
  hspi3.Init.TIMode = SPI_TIMODE_DISABLE;
  hspi3.Init.CRCCalculation = SPI_CRCCALCULATION_DISABLE;
  hspi3.Init.CRCPolynomial = 0x0;
  hspi3.Init.NSSPMode = SPI_NSS_PULSE_ENABLE;
  hspi3.Init.NSSPolarity = SPI_NSS_POLARITY_LOW;
  hspi3.Init.FifoThreshold = SPI_FIFO_THRESHOLD_01DATA;
  hspi3.Init.TxCRCInitializationPattern = SPI_CRC_INITIALIZATION_ALL_ZERO_PATTERN;
  hspi3.Init.RxCRCInitializationPattern = SPI_CRC_INITIALIZATION_ALL_ZERO_PATTERN;
  hspi3.Init.MasterSSIdleness = SPI_MASTER_SS_IDLENESS_00CYCLE;
  hspi3.Init.MasterInterDataIdleness = SPI_MASTER_INTERDATA_IDLENESS_00CYCLE;
  hspi3.Init.MasterReceiverAutoSusp = SPI_MASTER_RX_AUTOSUSP_DISABLE;
  hspi3.Init.MasterKeepIOState = SPI_MASTER_KEEP_IO_STATE_DISABLE;
  hspi3.Init.IOSwap = SPI_IO_SWAP_DISABLE;
  if (HAL_SPI_Init(&hspi3) != HAL_OK)
  {
    Error_Handler();
  }

}

static void MX_SPI4_Init(void)
{

  /* SPI4 parameter configuration*/
  hspi4.Instance = SPI4;
  hspi4.Init.Mode = SPI_MODE_MASTER;
  hspi4.Init.Direction = SPI_DIRECTION_2LINES;
  hspi4.Init.DataSize = SPI_DATASIZE_8BIT;
  hspi4.Init.CLKPolarity = SPI_POLARITY_LOW;
  hspi4.Init.CLKPhase = SPI_PHASE_1EDGE;
  hspi4.Init.NSS = SPI_NSS_SOFT;
  hspi4.Init.BaudRatePrescaler = SPI_BAUDRATEPRESCALER_16;
  hspi4.Init.FirstBit = SPI_FIRSTBIT_MSB;
  hspi4.Init.TIMode = SPI_TIMODE_DISABLE;
  hspi4.Init.CRCCalculation = SPI_CRCCALCULATION_DISABLE;
  hspi4.Init.CRCPolynomial = 0x0;
  hspi4.Init.NSSPMode = SPI_NSS_PULSE_DISABLE;
  hspi4.Init.NSSPolarity = SPI_NSS_POLARITY_LOW;
  hspi4.Init.FifoThreshold = SPI_FIFO_THRESHOLD_01DATA;
  hspi4.Init.TxCRCInitializationPattern = SPI_CRC_INITIALIZATION_ALL_ZERO_PATTERN;
  hspi4.Init.RxCRCInitializationPattern = SPI_CRC_INITIALIZATION_ALL_ZERO_PATTERN;
  hspi4.Init.MasterSSIdleness = SPI_MASTER_SS_IDLENESS_00CYCLE;
  hspi4.Init.MasterInterDataIdleness = SPI_MASTER_INTERDATA_IDLENESS_00CYCLE;
  hspi4.Init.MasterReceiverAutoSusp = SPI_MASTER_RX_AUTOSUSP_DISABLE;
  hspi4.Init.MasterKeepIOState = SPI_MASTER_KEEP_IO_STATE_DISABLE;
  hspi4.Init.IOSwap = SPI_IO_SWAP_DISABLE;
  if (HAL_SPI_Init(&hspi4) != HAL_OK)
  {
    Error_Handler();
  }

}

static void MX_TIM1_Init(void)
{

  TIM_MasterConfigTypeDef sMasterConfig = {0};
  TIM_OC_InitTypeDef sConfigOC = {0};
  TIM_BreakDeadTimeConfigTypeDef sBreakDeadTimeConfig = {0};

  htim1.Instance = TIM1;
  htim1.Init.Prescaler = 239;
  htim1.Init.CounterMode = TIM_COUNTERMODE_UP;
  htim1.Init.Period = 2499;
  htim1.Init.ClockDivision = TIM_CLOCKDIVISION_DIV1;
  htim1.Init.RepetitionCounter = 0;
  htim1.Init.AutoReloadPreload = TIM_AUTORELOAD_PRELOAD_DISABLE;
  if (HAL_TIM_PWM_Init(&htim1) != HAL_OK)
  {
    Error_Handler();
  }
  sMasterConfig.MasterOutputTrigger = TIM_TRGO_RESET;
  sMasterConfig.MasterOutputTrigger2 = TIM_TRGO2_RESET;
  sMasterConfig.MasterSlaveMode = TIM_MASTERSLAVEMODE_DISABLE;
  if (HAL_TIMEx_MasterConfigSynchronization(&htim1, &sMasterConfig) != HAL_OK)
  {
    Error_Handler();
  }
  sConfigOC.OCMode = TIM_OCMODE_PWM1;
  sConfigOC.Pulse = 0;
  sConfigOC.OCPolarity = TIM_OCPOLARITY_HIGH;
  sConfigOC.OCNPolarity = TIM_OCNPOLARITY_HIGH;
  sConfigOC.OCFastMode = TIM_OCFAST_DISABLE;
  sConfigOC.OCIdleState = TIM_OCIDLESTATE_RESET;
  sConfigOC.OCNIdleState = TIM_OCNIDLESTATE_RESET;
  if (HAL_TIM_PWM_ConfigChannel(&htim1, &sConfigOC, TIM_CHANNEL_1) != HAL_OK)
  {
    Error_Handler();
  }
  if (HAL_TIM_PWM_ConfigChannel(&htim1, &sConfigOC, TIM_CHANNEL_2) != HAL_OK)
  {
    Error_Handler();
  }
  if (HAL_TIM_PWM_ConfigChannel(&htim1, &sConfigOC, TIM_CHANNEL_3) != HAL_OK)
  {
    Error_Handler();
  }
  if (HAL_TIM_PWM_ConfigChannel(&htim1, &sConfigOC, TIM_CHANNEL_4) != HAL_OK)
  {
    Error_Handler();
  }
  sBreakDeadTimeConfig.OffStateRunMode = TIM_OSSR_DISABLE;
  sBreakDeadTimeConfig.OffStateIDLEMode = TIM_OSSI_DISABLE;
  sBreakDeadTimeConfig.LockLevel = TIM_LOCKLEVEL_OFF;
  sBreakDeadTimeConfig.DeadTime = 0;
  sBreakDeadTimeConfig.BreakState = TIM_BREAK_DISABLE;
  sBreakDeadTimeConfig.BreakPolarity = TIM_BREAKPOLARITY_HIGH;
  sBreakDeadTimeConfig.BreakFilter = 0;
  sBreakDeadTimeConfig.Break2State = TIM_BREAK2_DISABLE;
  sBreakDeadTimeConfig.Break2Polarity = TIM_BREAK2POLARITY_HIGH;
  sBreakDeadTimeConfig.Break2Filter = 0;
  sBreakDeadTimeConfig.AutomaticOutput = TIM_AUTOMATICOUTPUT_DISABLE;
  if (HAL_TIMEx_ConfigBreakDeadTime(&htim1, &sBreakDeadTimeConfig) != HAL_OK)
  {
    Error_Handler();
  }
  HAL_TIM_MspPostInit(&htim1);

}

static void MX_TIM2_Init(void)
{

  TIM_ClockConfigTypeDef sClockSourceConfig = {0};
  TIM_MasterConfigTypeDef sMasterConfig = {0};

  htim2.Instance = TIM2;
  htim2.Init.Prescaler = 239;
  htim2.Init.CounterMode = TIM_COUNTERMODE_UP;
  htim2.Init.Period = 499;
  htim2.Init.ClockDivision = TIM_CLOCKDIVISION_DIV1;
  htim2.Init.AutoReloadPreload = TIM_AUTORELOAD_PRELOAD_DISABLE;
  if (HAL_TIM_Base_Init(&htim2) != HAL_OK)
  {
    Error_Handler();
  }
  sClockSourceConfig.ClockSource = TIM_CLOCKSOURCE_INTERNAL;
  if (HAL_TIM_ConfigClockSource(&htim2, &sClockSourceConfig) != HAL_OK)
  {
    Error_Handler();
  }
  sMasterConfig.MasterOutputTrigger = TIM_TRGO_RESET;
  sMasterConfig.MasterSlaveMode = TIM_MASTERSLAVEMODE_DISABLE;
  if (HAL_TIMEx_MasterConfigSynchronization(&htim2, &sMasterConfig) != HAL_OK)
  {
    Error_Handler();
  }

}

static void MX_TIM3_Init(void)
{

  TIM_ClockConfigTypeDef sClockSourceConfig = {0};
  TIM_MasterConfigTypeDef sMasterConfig = {0};

  htim3.Instance = TIM3;
  htim3.Init.Prescaler = 23999;
  htim3.Init.CounterMode = TIM_COUNTERMODE_UP;
  htim3.Init.Period = 99;
  htim3.Init.ClockDivision = TIM_CLOCKDIVISION_DIV1;
  htim3.Init.AutoReloadPreload = TIM_AUTORELOAD_PRELOAD_DISABLE;
  if (HAL_TIM_Base_Init(&htim3) != HAL_OK)
  {
    Error_Handler();
  }
  sClockSourceConfig.ClockSource = TIM_CLOCKSOURCE_INTERNAL;
  if (HAL_TIM_ConfigClockSource(&htim3, &sClockSourceConfig) != HAL_OK)
  {
    Error_Handler();
  }
  sMasterConfig.MasterOutputTrigger = TIM_TRGO_RESET;
  sMasterConfig.MasterSlaveMode = TIM_MASTERSLAVEMODE_DISABLE;
  if (HAL_TIMEx_MasterConfigSynchronization(&htim3, &sMasterConfig) != HAL_OK)
  {
    Error_Handler();
  }

}

static void MX_TIM4_Init(void)
{

  TIM_MasterConfigTypeDef sMasterConfig = {0};
  TIM_OC_InitTypeDef sConfigOC = {0};

  htim4.Instance = TIM4;
  htim4.Init.Prescaler = 0;
  htim4.Init.CounterMode = TIM_COUNTERMODE_UP;
  htim4.Init.Period = 65535;
  htim4.Init.ClockDivision = TIM_CLOCKDIVISION_DIV1;
  htim4.Init.AutoReloadPreload = TIM_AUTORELOAD_PRELOAD_DISABLE;
  if (HAL_TIM_PWM_Init(&htim4) != HAL_OK)
  {
    Error_Handler();
  }
  sMasterConfig.MasterOutputTrigger = TIM_TRGO_RESET;
  sMasterConfig.MasterSlaveMode = TIM_MASTERSLAVEMODE_DISABLE;
  if (HAL_TIMEx_MasterConfigSynchronization(&htim4, &sMasterConfig) != HAL_OK)
  {
    Error_Handler();
  }
  sConfigOC.OCMode = TIM_OCMODE_PWM1;
  sConfigOC.Pulse = 0;
  sConfigOC.OCPolarity = TIM_OCPOLARITY_HIGH;
  sConfigOC.OCFastMode = TIM_OCFAST_DISABLE;
  if (HAL_TIM_PWM_ConfigChannel(&htim4, &sConfigOC, TIM_CHANNEL_3) != HAL_OK)
  {
    Error_Handler();
  }
  if (HAL_TIM_PWM_ConfigChannel(&htim4, &sConfigOC, TIM_CHANNEL_4) != HAL_OK)
  {
    Error_Handler();
  }
  HAL_TIM_MspPostInit(&htim4);

}

static void MX_USART1_UART_Init(void)
{

  huart1.Instance = USART1;
  huart1.Init.BaudRate = 115200;
  huart1.Init.WordLength = UART_WORDLENGTH_8B;
  huart1.Init.StopBits = UART_STOPBITS_1;
  huart1.Init.Parity = UART_PARITY_NONE;
  huart1.Init.Mode = UART_MODE_TX_RX;
  huart1.Init.HwFlowCtl = UART_HWCONTROL_NONE;
  huart1.Init.OverSampling = UART_OVERSAMPLING_16;
  huart1.Init.OneBitSampling = UART_ONE_BIT_SAMPLE_DISABLE;
  huart1.Init.ClockPrescaler = UART_PRESCALER_DIV1;
  huart1.AdvancedInit.AdvFeatureInit = UART_ADVFEATURE_SWAP_INIT;
  huart1.AdvancedInit.Swap = UART_ADVFEATURE_SWAP_ENABLE;
  if (HAL_UART_Init(&huart1) != HAL_OK)
  {
    Error_Handler();
  }
  if (HAL_UARTEx_SetTxFifoThreshold(&huart1, UART_TXFIFO_THRESHOLD_1_8) != HAL_OK)
  {
    Error_Handler();
  }
  if (HAL_UARTEx_SetRxFifoThreshold(&huart1, UART_RXFIFO_THRESHOLD_1_8) != HAL_OK)
  {
    Error_Handler();
  }
  if (HAL_UARTEx_DisableFifoMode(&huart1) != HAL_OK)
  {
    Error_Handler();
  }

}

static void MX_USART2_UART_Init(void)
{

  huart2.Instance = USART2;
  huart2.Init.BaudRate = 9600;
  huart2.Init.WordLength = UART_WORDLENGTH_8B;
  huart2.Init.StopBits = UART_STOPBITS_1;
  huart2.Init.Parity = UART_PARITY_NONE;
  huart2.Init.Mode = UART_MODE_TX_RX;
  huart2.Init.HwFlowCtl = UART_HWCONTROL_NONE;
  huart2.Init.OverSampling = UART_OVERSAMPLING_16;
  huart2.Init.OneBitSampling = UART_ONE_BIT_SAMPLE_DISABLE;
  huart2.Init.ClockPrescaler = UART_PRESCALER_DIV1;
  huart2.AdvancedInit.AdvFeatureInit = UART_ADVFEATURE_NO_INIT;
  if (HAL_UART_Init(&huart2) != HAL_OK)
  {
    Error_Handler();
  }
  if (HAL_UARTEx_SetTxFifoThreshold(&huart2, UART_TXFIFO_THRESHOLD_1_8) != HAL_OK)
  {
    Error_Handler();
  }
  if (HAL_UARTEx_SetRxFifoThreshold(&huart2, UART_RXFIFO_THRESHOLD_1_8) != HAL_OK)
  {
    Error_Handler();
  }
  if (HAL_UARTEx_DisableFifoMode(&huart2) != HAL_OK)
  {
    Error_Handler();
  }

}

static void MX_USART6_UART_Init(void)
{

  huart6.Instance = USART6;
  huart6.Init.BaudRate = 9600;
  huart6.Init.WordLength = UART_WORDLENGTH_8B;
  huart6.Init.StopBits = UART_STOPBITS_1;
  huart6.Init.Parity = UART_PARITY_NONE;
  huart6.Init.Mode = UART_MODE_TX_RX;
  huart6.Init.HwFlowCtl = UART_HWCONTROL_NONE;
  huart6.Init.OverSampling = UART_OVERSAMPLING_16;
  huart6.Init.OneBitSampling = UART_ONE_BIT_SAMPLE_DISABLE;
  huart6.Init.ClockPrescaler = UART_PRESCALER_DIV1;
  huart6.AdvancedInit.AdvFeatureInit = UART_ADVFEATURE_NO_INIT;
  if (HAL_UART_Init(&huart6) != HAL_OK)
  {
    Error_Handler();
  }
  if (HAL_UARTEx_SetTxFifoThreshold(&huart6, UART_TXFIFO_THRESHOLD_1_8) != HAL_OK)
  {
    Error_Handler();
  }
  if (HAL_UARTEx_SetRxFifoThreshold(&huart6, UART_RXFIFO_THRESHOLD_1_8) != HAL_OK)
  {
    Error_Handler();
  }
  if (HAL_UARTEx_DisableFifoMode(&huart6) != HAL_OK)
  {
    Error_Handler();
  }

}

static void MX_DMA_Init(void)
{

  /* DMA controller clock enable */
  __HAL_RCC_DMA1_CLK_ENABLE();
  __HAL_RCC_DMA2_CLK_ENABLE();

  /* DMA interrupt init */
  /* DMA1_Stream0_IRQn interrupt configuration */
  HAL_NVIC_SetPriority(DMA1_Stream0_IRQn, 0, 0);
  HAL_NVIC_EnableIRQ(DMA1_Stream0_IRQn);
  /* DMA1_Stream1_IRQn interrupt configuration */
  HAL_NVIC_SetPriority(DMA1_Stream1_IRQn, 0, 0);
  HAL_NVIC_EnableIRQ(DMA1_Stream1_IRQn);
  /* DMA1_Stream2_IRQn interrupt configuration */
  HAL_NVIC_SetPriority(DMA1_Stream2_IRQn, 0, 0);
  HAL_NVIC_EnableIRQ(DMA1_Stream2_IRQn);
  /* DMA1_Stream3_IRQn interrupt configuration */
  HAL_NVIC_SetPriority(DMA1_Stream3_IRQn, 0, 0);
  HAL_NVIC_EnableIRQ(DMA1_Stream3_IRQn);
  /* DMA1_Stream4_IRQn interrupt configuration */
  HAL_NVIC_SetPriority(DMA1_Stream4_IRQn, 0, 0);
  HAL_NVIC_EnableIRQ(DMA1_Stream4_IRQn);
  /* DMA1_Stream5_IRQn interrupt configuration */
  HAL_NVIC_SetPriority(DMA1_Stream5_IRQn, 0, 0);
  HAL_NVIC_EnableIRQ(DMA1_Stream5_IRQn);
  /* DMA1_Stream6_IRQn interrupt configuration */
  HAL_NVIC_SetPriority(DMA1_Stream6_IRQn, 0, 0);
  HAL_NVIC_EnableIRQ(DMA1_Stream6_IRQn);
  /* DMA1_Stream7_IRQn interrupt configuration */
  HAL_NVIC_SetPriority(DMA1_Stream7_IRQn, 0, 0);
  HAL_NVIC_EnableIRQ(DMA1_Stream7_IRQn);
  /* DMA2_Stream0_IRQn interrupt configuration */
  HAL_NVIC_SetPriority(DMA2_Stream0_IRQn, 0, 0);
  HAL_NVIC_EnableIRQ(DMA2_Stream0_IRQn);

}

static void MX_GPIO_Init(void)
{
  GPIO_InitTypeDef GPIO_InitStruct = {0};

  /* GPIO Ports Clock Enable */
  __HAL_RCC_GPIOE_CLK_ENABLE();
  __HAL_RCC_GPIOC_CLK_ENABLE();
  __HAL_RCC_GPIOH_CLK_ENABLE();
  __HAL_RCC_GPIOA_CLK_ENABLE();
  __HAL_RCC_GPIOB_CLK_ENABLE();
  __HAL_RCC_GPIOD_CLK_ENABLE();

  /*Configure GPIO pin Output Level */
  HAL_GPIO_WritePin(SPI4_CS_GPIO_Port, SPI4_CS_Pin, GPIO_PIN_SET);

  /*Configure GPIO pin Output Level */
  HAL_GPIO_WritePin(GPIOC, SPI4_RESET_Pin|SPI1_RESET_Pin|GPIO_PIN_8, GPIO_PIN_RESET);

  /*Configure GPIO pin Output Level */
  HAL_GPIO_WritePin(UART2_RESET_GPIO_Port, UART2_RESET_Pin, GPIO_PIN_SET);

  /*Configure GPIO pin Output Level */
  HAL_GPIO_WritePin(SPI1_CS_GPIO_Port, SPI1_CS_Pin, GPIO_PIN_RESET);

  /*Configure GPIO pin Output Level */
  HAL_GPIO_WritePin(SPI1_WAKE_GPIO_Port, SPI1_WAKE_Pin, GPIO_PIN_RESET);

  /*Configure GPIO pin Output Level */
  HAL_GPIO_WritePin(SPI2_CS_GPIO_Port, SPI2_CS_Pin, GPIO_PIN_SET);

  /*Configure GPIO pin Output Level */
  HAL_GPIO_WritePin(GPIOD, LED3_Pin|LED2_Pin|LED1_Pin|GPIO_PIN_11
                          |GPIO_PIN_12|GPIO_PIN_13|GPIO_PIN_14|GPIO_PIN_15
                          |SPI3_CS_Pin, GPIO_PIN_RESET);

  /*Configure GPIO pin : SPI4_CS_Pin */
  GPIO_InitStruct.Pin = SPI4_CS_Pin;
  GPIO_InitStruct.Mode = GPIO_MODE_OUTPUT_PP;
  GPIO_InitStruct.Pull = GPIO_NOPULL;
  GPIO_InitStruct.Speed = GPIO_SPEED_FREQ_LOW;
  HAL_GPIO_Init(SPI4_CS_GPIO_Port, &GPIO_InitStruct);

  /*Configure GPIO pin : SPI4_INT_Pin */
  GPIO_InitStruct.Pin = SPI4_INT_Pin;
  GPIO_InitStruct.Mode = GPIO_MODE_IT_RISING;
  GPIO_InitStruct.Pull = GPIO_NOPULL;
  HAL_GPIO_Init(SPI4_INT_GPIO_Port, &GPIO_InitStruct);

  /*Configure GPIO pins : SPI4_RESET_Pin SPI1_RESET_Pin PC8 */
  GPIO_InitStruct.Pin = SPI4_RESET_Pin|SPI1_RESET_Pin|GPIO_PIN_8;
  GPIO_InitStruct.Mode = GPIO_MODE_OUTPUT_PP;
  GPIO_InitStruct.Pull = GPIO_NOPULL;
  GPIO_InitStruct.Speed = GPIO_SPEED_FREQ_LOW;
  HAL_GPIO_Init(GPIOC, &GPIO_InitStruct);

  /*Configure GPIO pins : UART2_RESET_Pin SPI1_CS_Pin */
  GPIO_InitStruct.Pin = UART2_RESET_Pin|SPI1_CS_Pin;
  GPIO_InitStruct.Mode = GPIO_MODE_OUTPUT_PP;
  GPIO_InitStruct.Pull = GPIO_NOPULL;
  GPIO_InitStruct.Speed = GPIO_SPEED_FREQ_LOW;
  HAL_GPIO_Init(GPIOA, &GPIO_InitStruct);

  /*Configure GPIO pins : SPI1_WAKE_Pin SPI2_CS_Pin */
  GPIO_InitStruct.Pin = SPI1_WAKE_Pin|SPI2_CS_Pin;
  GPIO_InitStruct.Mode = GPIO_MODE_OUTPUT_PP;
  GPIO_InitStruct.Pull = GPIO_NOPULL;
  GPIO_InitStruct.Speed = GPIO_SPEED_FREQ_LOW;
  HAL_GPIO_Init(GPIOB, &GPIO_InitStruct);

  /*Configure GPIO pins : SPI1_INT_Pin SPI2_INT_Pin I2C1_INT_Pin */
  GPIO_InitStruct.Pin = SPI1_INT_Pin|SPI2_INT_Pin|I2C1_INT_Pin;
  GPIO_InitStruct.Mode = GPIO_MODE_IT_RISING;
  GPIO_InitStruct.Pull = GPIO_NOPULL;
  HAL_GPIO_Init(GPIOB, &GPIO_InitStruct);

  /*Configure GPIO pins : LED3_Pin LED2_Pin LED1_Pin PD11
                           PD12 PD13 PD14 PD15
                           SPI3_CS_Pin */
  GPIO_InitStruct.Pin = LED3_Pin|LED2_Pin|LED1_Pin|GPIO_PIN_11
                          |GPIO_PIN_12|GPIO_PIN_13|GPIO_PIN_14|GPIO_PIN_15
                          |SPI3_CS_Pin;
  GPIO_InitStruct.Mode = GPIO_MODE_OUTPUT_PP;
  GPIO_InitStruct.Pull = GPIO_NOPULL;
  GPIO_InitStruct.Speed = GPIO_SPEED_FREQ_LOW;
  HAL_GPIO_Init(GPIOD, &GPIO_InitStruct);

  /*Configure GPIO pins : SW_U_Pin SW_D_Pin SW_L_Pin SW_R_Pin
                           SW_P_Pin */
  GPIO_InitStruct.Pin = SW_U_Pin|SW_D_Pin|SW_L_Pin|SW_R_Pin
                          |SW_P_Pin;
  GPIO_InitStruct.Mode = GPIO_MODE_INPUT;
  GPIO_InitStruct.Pull = GPIO_PULLUP;
  HAL_GPIO_Init(GPIOD, &GPIO_InitStruct);

  /*AnalogSwitch Config */
  HAL_SYSCFG_AnalogSwitchConfig(SYSCFG_SWITCH_PA1, SYSCFG_SWITCH_PA1_CLOSE);

  /* EXTI interrupt init*/
  HAL_NVIC_SetPriority(SPI1_INT_EXTI_IRQn, 0, 0);
  HAL_NVIC_EnableIRQ(SPI1_INT_EXTI_IRQn);

  HAL_NVIC_SetPriority(SPI4_INT_EXTI_IRQn, 0, 0);
  HAL_NVIC_EnableIRQ(SPI4_INT_EXTI_IRQn);

  HAL_NVIC_SetPriority(I2C1_INT_EXTI_IRQn, 0, 0);
  HAL_NVIC_EnableIRQ(I2C1_INT_EXTI_IRQn);

  HAL_NVIC_SetPriority(SPI2_INT_EXTI_IRQn, 0, 0);
  HAL_NVIC_EnableIRQ(SPI2_INT_EXTI_IRQn);

}

 /* MPU Configuration */

void MPU_Config(void)
{
  MPU_Region_InitTypeDef MPU_InitStruct = {0};

  /* Disables the MPU */
  HAL_MPU_Disable();

  /** Initializes and configures the Region and the memory to be protected
  */
  MPU_InitStruct.Enable = MPU_REGION_ENABLE;
  MPU_InitStruct.Number = MPU_REGION_NUMBER0;
  MPU_InitStruct.BaseAddress = 0x0;
  MPU_InitStruct.Size = MPU_REGION_SIZE_4GB;
  MPU_InitStruct.SubRegionDisable = 0x87;
  MPU_InitStruct.TypeExtField = MPU_TEX_LEVEL0;
  MPU_InitStruct.AccessPermission = MPU_REGION_NO_ACCESS;
  MPU_InitStruct.DisableExec = MPU_INSTRUCTION_ACCESS_DISABLE;
  MPU_InitStruct.IsShareable = MPU_ACCESS_SHAREABLE;
  MPU_InitStruct.IsCacheable = MPU_ACCESS_NOT_CACHEABLE;
  MPU_InitStruct.IsBufferable = MPU_ACCESS_NOT_BUFFERABLE;

  HAL_MPU_ConfigRegion(&MPU_InitStruct);
  /* Enables the MPU */
  HAL_MPU_Enable(MPU_PRIVILEGED_DEFAULT);

}

void Error_Handler(void)
{
  __disable_irq();
  while (1) {
  }
}
#ifdef USE_FULL_ASSERT
/**
  * @brief  Reports the name of the source file and the source line number
  *         where the assert_param error has occurred.
  * @param  file: pointer to the source file name
  * @param  line: assert_param error line source number
  * @retval None
  */
void assert_failed(uint8_t *file, uint32_t line)
{
  /* USER CODE BEGIN 6 */
  /* User can add his own implementation to report the file name and line
     number, ex: printf("Wrong parameters value: file %s on line %d\r\n", file,
     line) */
  /* USER CODE END 6 */
}
#endif /* USE_FULL_ASSERT */
